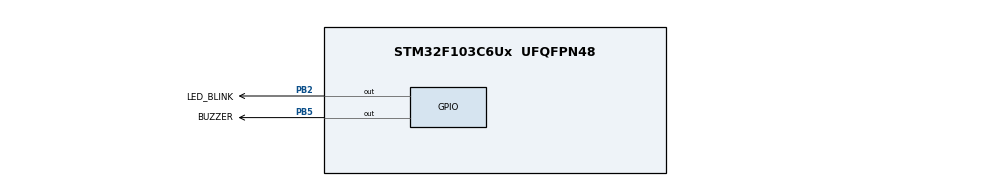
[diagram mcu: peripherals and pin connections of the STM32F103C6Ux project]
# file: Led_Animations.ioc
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Mcu.Family=STM32F1
Mcu.Name=STM32F103C6Ux
Mcu.Package=UFQFPN48
NVIC.PriorityGroup=NVIC_PRIORITYGROUP_4
NVIC.TIM2_IRQn=true\:0\:0\:false\:false\:true\:true\:true\:true
PB2.GPIO_Label=LED_BLINK
PB2.Signal=GPIO_Output
PB5.GPIO_Label=BUZZER
PB5.Signal=GPIO_Output
ProjectManager.HeapSize=0x200
ProjectManager.StackSize=0x400
ProjectManager.TargetToolchain=STM32CubeIDE
RCC.APB1Freq_Value=8000000
RCC.APB2Freq_Value=8000000
TIM2.Period=9
TIM2.Prescaler=7999
VP_SYS_VS_ND.Mode=No_Debug
VP_TIM2_VS_ClockSourceINT.Mode=Internal
board=custom

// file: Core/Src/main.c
/* USER CODE BEGIN Header */
/**
  ******************************************************************************
  * @file           : main.c
  * @brief          : Main program body
  ******************************************************************************
  * @attention
  *
  * Copyright (c) 2022 STMicroelectronics.
  * All rights reserved.
  *
  * This software is licensed under terms that can be found in the LICENSE file
  * in the root directory of this software component.
  * If no LICENSE file comes with this software, it is provided AS-IS.
  *
  ******************************************************************************
  */
/* USER CODE END Header */
#include "main.h"

/* USER CODE BEGIN PTD */
typedef enum { ON, OFF } status;
status ledState = ON;
status buzzerState = ON;
/* USER CODE END PTD */

/* USER CODE BEGIN PD */
//#define 	DELAYTIME 	10
/* USER CODE END PD */

TIM_HandleTypeDef htim2;

/* USER CODE BEGIN PV */
const uint8_t delayTime = 10;
static uint8_t systemStatus = 0;
const uint32_t systemDelayTime = 60000 / delayTime;
const uint32_t illuminationDelayTime = systemDelayTime / 20;
static uint32_t ledTimeOn, ledTimeOff, buzzerTimeOn, buzzerTimeOff;
static uint32_t ledCounter = 0, buzzerCounter = 0, illuminationCounter = 0, systemCounter = 0;
static uint32_t illuminationValue = 0;
/* USER CODE END PV */

void SystemClock_Config(void);
static void MX_GPIO_Init(void);
static void MX_TIM2_Init(void);
/* USER CODE BEGIN PFP */
void ledSetup(uint32_t timeOn, uint32_t timeOff);
void buzzerSteup(uint32_t timeOn, uint32_t timeOff);
void ledOperation(void);
void buzzerOperation(void);
void turnLedOn(void);
void turnLedOff(void);
void ledDutyCycle(uint32_t percent, uint32_t duration);
void ledIllumination(void);
void buzzerDutyCycle(uint32_t percent, uint32_t duration);
void updateSystemStatus(void);
void timerInterruptServiceRoutine(void);
void systemStatusOperation(void);
/* USER CODE END PFP */

/* USER CODE BEGIN 0 */
void turnLedOn(void) {
	HAL_GPIO_WritePin(LED_BLINK_GPIO_Port, LED_BLINK_Pin, GPIO_PIN_RESET);
}

void turnLedOff(void) {
	HAL_GPIO_WritePin(LED_BLINK_GPIO_Port, LED_BLINK_Pin, GPIO_PIN_SET);
}

void turnBuzzerOn(void) {
	HAL_GPIO_WritePin(BUZZER_GPIO_Port, BUZZER_Pin, GPIO_PIN_SET);
}

void turnBuzzerOff(void) {
	HAL_GPIO_WritePin(BUZZER_GPIO_Port, BUZZER_Pin, GPIO_PIN_RESET);
}

void ledSetup(uint32_t timeOn, uint32_t timeOff) {
	ledTimeOn = timeOn;
	ledTimeOff = timeOff;
	if(delayTime != 0) {
		 ledTimeOn /= delayTime;
		 ledTimeOff /= delayTime;
	}
}

void buzzerSetup(uint32_t timeOn, uint32_t timeOff) {
	buzzerTimeOn = timeOn;
	buzzerTimeOff = timeOff;
	if(delayTime != 0) {
		 buzzerTimeOn /= delayTime;
		 buzzerTimeOff /= delayTime;
	}
}

void ledDutyCycle(uint32_t percent, uint32_t duration) {
	ledTimeOn = percent * duration / 100;
	ledTimeOff = duration - ledTimeOn;
}

void buzzerDutyCycle(uint32_t percent, uint32_t duration) {
	buzzerTimeOn = percent * duration / 100;
	buzzerTimeOff = duration - buzzerTimeOn;
}

void ledOperation(void) {
	if(ledTimeOn == 0) {
		turnLedOff();
		return;
	}
	if(ledTimeOff == 0) {
		turnLedOn();
		return;
	}
	ledCounter++;
	switch(ledState) {
	case ON: {
		if(ledCounter <= ledTimeOn) {
			turnLedOn();
		}
		else {
			ledState = OFF;
			ledCounter = 0;
		}
		break;
	}
	case OFF: {
		if(ledCounter <= ledTimeOff) {
			turnLedOff();
		}
		else {
			ledState = ON;
			ledCounter = 0;
		}
		break;
	}
	default: break;
	}
}

void ledIllumination(void) {
	illuminationCounter = (illuminationCounter + 1) % illuminationDelayTime;
	if(illuminationCounter == 0) {
		illuminationValue = (illuminationValue + 10) % 100;
		ledDutyCycle(illuminationValue, illuminationDelayTime);
	}
}

void buzzerOperation(void) {
	if(buzzerTimeOn == 0) {
		turnBuzzerOff();
		return;
	}
	if(buzzerTimeOff == 0) {
		turnBuzzerOn();
		return;
	}
	buzzerCounter++;
	switch(buzzerState) {
	case ON: {
		if(buzzerCounter <= buzzerTimeOn) {
			turnBuzzerOn();
		}
		else {
			buzzerState = OFF;
			buzzerCounter = 0;
		}
		break;
	}
	case OFF: {
		if(buzzerCounter <= buzzerTimeOff) {
			turnBuzzerOff();
		}
		else {
			buzzerState = ON;
			buzzerCounter = 0;
		}
		break;
	}
	default: break;
	}
}

void updateSystemStatus(void) {
	systemCounter = (systemCounter + 1) % systemDelayTime;
	if(systemCounter == 0) {
		systemStatus = (systemStatus + 1) % 4;
	}
}

void timerInterruptServiceRoutine(void) {
	updateSystemStatus();
}

void systemStatusOperation(void) {
	switch(systemStatus) {
	case 0: {
		ledSetup(1000, 1000);
		buzzerSetup(500, 500);
		break;
	}
	case 1: {
		ledIllumination();
		buzzerSetup(5000, 5000);
		break;
	}
	case 2: {
		ledSetup(200, 200);
		buzzerSetup(1000, 1000);
		break;
	}
	case 3: {
		ledDutyCycle(100, systemDelayTime);
		buzzerDutyCycle(100, systemDelayTime);
		break;
	}
	default: break;
	}
}
/* USER CODE END 0 */

int main(void)
{

  /* MCU Configuration--------------------------------------------------------*/

  /* Reset of all peripherals, Initializes the Flash interface and the Systick. */
  HAL_Init();

  /* Configure the system clock */
  SystemClock_Config();

  /* Initialize all configured peripherals */
  MX_GPIO_Init();
  MX_TIM2_Init();
  /* USER CODE BEGIN 2 */
  HAL_TIM_Base_Start_IT(&htim2);
  /* USER CODE END 2 */

  /* Infinite loop */
  while (1)
  {

  }
}

void SystemClock_Config(void)
{
  RCC_OscInitTypeDef RCC_OscInitStruct = {0};
  RCC_ClkInitTypeDef RCC_ClkInitStruct = {0};

  /** Initializes the RCC Oscillators according to the specified parameters
  * in the RCC_OscInitTypeDef structure.
  */
  RCC_OscInitStruct.OscillatorType = RCC_OSCILLATORTYPE_HSI;
  RCC_OscInitStruct.HSIState = RCC_HSI_ON;
  RCC_OscInitStruct.HSICalibrationValue = RCC_HSICALIBRATION_DEFAULT;
  RCC_OscInitStruct.PLL.PLLState = RCC_PLL_NONE;
  if (HAL_RCC_OscConfig(&RCC_OscInitStruct) != HAL_OK)
  {
    Error_Handler();
  }

  /** Initializes the CPU, AHB and APB buses clocks
  */
  RCC_ClkInitStruct.ClockType = RCC_CLOCKTYPE_HCLK|RCC_CLOCKTYPE_SYSCLK
                              |RCC_CLOCKTYPE_PCLK1|RCC_CLOCKTYPE_PCLK2;
  RCC_ClkInitStruct.SYSCLKSource = RCC_SYSCLKSOURCE_HSI;
  RCC_ClkInitStruct.AHBCLKDivider = RCC_SYSCLK_DIV1;
  RCC_ClkInitStruct.APB1CLKDivider = RCC_HCLK_DIV1;
  RCC_ClkInitStruct.APB2CLKDivider = RCC_HCLK_DIV1;

  if (HAL_RCC_ClockConfig(&RCC_ClkInitStruct, FLASH_LATENCY_0) != HAL_OK)
  {
    Error_Handler();
  }
}

static void MX_TIM2_Init(void)
{

  TIM_ClockConfigTypeDef sClockSourceConfig = {0};
  TIM_MasterConfigTypeDef sMasterConfig = {0};

  htim2.Instance = TIM2;
  htim2.Init.Prescaler = 7999;
  htim2.Init.CounterMode = TIM_COUNTERMODE_UP;
  htim2.Init.Period = 9;
  htim2.Init.ClockDivision = TIM_CLOCKDIVISION_DIV1;
  htim2.Init.AutoReloadPreload = TIM_AUTORELOAD_PRELOAD_DISABLE;
  if (HAL_TIM_Base_Init(&htim2) != HAL_OK)
  {
    Error_Handler();
  }
  sClockSourceConfig.ClockSource = TIM_CLOCKSOURCE_INTERNAL;
  if (HAL_TIM_ConfigClockSource(&htim2, &sClockSourceConfig) != HAL_OK)
  {
    Error_Handler();
  }
  sMasterConfig.MasterOutputTrigger = TIM_TRGO_RESET;
  sMasterConfig.MasterSlaveMode = TIM_MASTERSLAVEMODE_DISABLE;
  if (HAL_TIMEx_MasterConfigSynchronization(&htim2, &sMasterConfig) != HAL_OK)
  {
    Error_Handler();
  }

}

static void MX_GPIO_Init(void)
{
  GPIO_InitTypeDef GPIO_InitStruct = {0};

  /* GPIO Ports Clock Enable */
  __HAL_RCC_GPIOB_CLK_ENABLE();

  /*Configure GPIO pin Output Level */
  HAL_GPIO_WritePin(GPIOB, LED_BLINK_Pin|BUZZER_Pin, GPIO_PIN_RESET);

  /*Configure GPIO pins : LED_BLINK_Pin BUZZER_Pin */
  GPIO_InitStruct.Pin = LED_BLINK_Pin|BUZZER_Pin;
  GPIO_InitStruct.Mode = GPIO_MODE_OUTPUT_PP;
  GPIO_InitStruct.Pull = GPIO_NOPULL;
  GPIO_InitStruct.Speed = GPIO_SPEED_FREQ_LOW;
  HAL_GPIO_Init(GPIOB, &GPIO_InitStruct);

}

/* USER CODE BEGIN 4 */
void HAL_TIM_PeriodElapsedCallback(TIM_HandleTypeDef *htim) {
	timerInterruptServiceRoutine();
	systemStatusOperation();
	ledOperation();
	buzzerOperation();
}
/* USER CODE END 4 */

void Error_Handler(void)
{
  __disable_irq();
  while (1)
  {
  }
}
